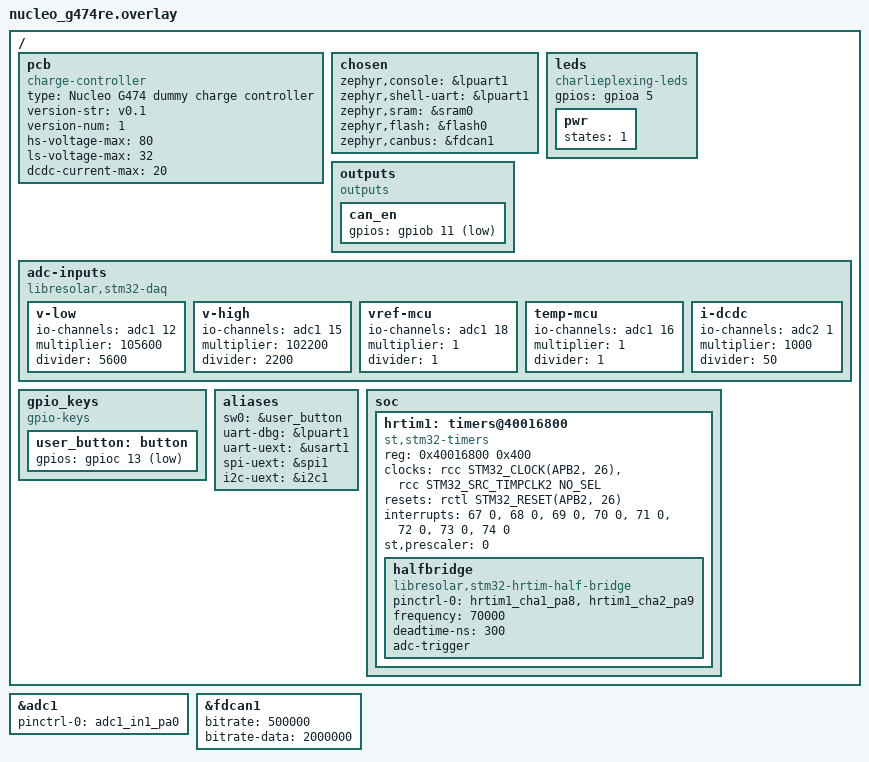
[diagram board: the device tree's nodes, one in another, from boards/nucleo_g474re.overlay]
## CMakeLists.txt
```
# Copyright (c) The Libre Solar Project Contributors
# SPDX-License-Identifier: Apache-2.0

set(BOARD_ROOT ${CMAKE_SOURCE_DIR}/..)
set(DTS_ROOT ${CMAKE_SOURCE_DIR}/..)

cmake_minimum_required(VERSION 3.13.1)
find_package(Zephyr REQUIRED HINTS $ENV{ZEPHYR_BASE})

project(libre_solar_charge_controller)

add_subdirectory(src)

# determine git tag and commit hash for automatic firmware versioning
find_package(Git)
if(GIT_FOUND)
    execute_process(
        COMMAND ${GIT_EXECUTABLE} describe --long --dirty --tags
        OUTPUT_VARIABLE FIRMWARE_VERSION_ID
        OUTPUT_STRIP_TRAILING_WHITESPACE)
else()
    set(FIRMWARE_VERSION_ID "unknown")
endif()
add_definitions(-DFIRMWARE_VERSION_ID="${FIRMWARE_VERSION_ID}")
```

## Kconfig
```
# Copyright (c) The Libre Solar Project Contributors
# SPDX-License-Identifier: Apache-2.0

mainmenu "Libre Solar Charge Controller Firmware"

#
# Invisible (board-specific) Kconfig symbols
#

config CONTROL_FREQUENCY
    int
    default 10
    help
      Main control function frequency (Hz)

      Frequencies higher than 10 Hz caused issues with MPPT control during lab test with
      PV simulator. Might be different with actual solar panel.

config DCDC_DUTY_STEP_SIZE
    int
    default 3 if SOC_SERIES_STM32G4X
    default 1
    help
      Duty cycle change per control step of the DC/DC MPPT algorithm in timer counts of the
      half bridge.

      Larger steps are used for faster microcontrollers, as their half-bridge timers have a
      higher resolution.

config HS_MOSFET_FAIL_SAFE_PROTECTION
    bool
    default y
    depends on $(dt_node_bool_prop,/pcb,ls-fuse)
    help
      If enabled, the DC/DC control function will detect if the high-side MOSFET has failed
      short and trip the fuse by switching the low-side MOSFET continuously on. This will prevent
      accidental overcharging of the battery.

      Only available if the board has a fuse at the low-side terminal (ls-fuse property of the
      pcb devicetree node).

#
# Visible (user-configurable) Kconfig symbols
#

menu "Charge Controller Setup"

choice
    prompt "High-voltage terminal"
    depends on $(dt_nodelabel_enabled,halfbridge)
    help
      Select the device connected to the high-voltage
      side terminal of the DC/DC converter.

    config HV_TERMINAL_SOLAR
        bool "Solar panel"

    config HV_TERMINAL_NANOGRID
        bool "DC nanogrid"

    config HV_TERMINAL_GENERATOR
        bool "DC generator, e.g. wind turbine"

    config HV_TERMINAL_BATTERY
        bool "Battery, e.g. electric bicycle"
endchoice


choice
    prompt "Low-voltage terminal"
    help
      Select the device connected to the low-voltage side
      of the charge controller (usually battery terminal).

    config LV_TERMINAL_BATTERY
        depends on !HV_TERMINAL_BATTERY
        bool "Battery 12V/24V"

    config LV_TERMINAL_SOLAR
        depends on HV_TERMINAL_BATTERY || HV_TERMINAL_NANOGRID
        bool "Solar panel"
endchoice


choice
    prompt "PWM terminal"
    depends on $(dt_nodelabel_enabled,pwm_switch)
    help
      Select the device connected to the PWM switch (currently
      only solar panel possible)

    config PWM_TERMINAL_SOLAR
        depends on LV_TERMINAL_BATTERY && !HV_TERMINAL_SOLAR
        bool "Solar panel"
endchoice


menu "Battery default settings"

config BAT_CAPACITY_AH
    int "Battery nominal capacity in Ah"
    range 10 1000
    default 50
    help
      Nominal battery capacity or sum of parallel cells capacity

choice
    prompt "Battery type"
    default BAT_TYPE_GEL
    help
      Select the type of the single cells inside the battery
      to determine voltage set points. Total voltage set points
      are multiplied with the selected number of cells.

    config BAT_TYPE_CUSTOM
        bool "Custom type"

    config BAT_TYPE_FLOODED
        bool "Flooded (wet) lead-acid"

    config BAT_TYPE_GEL
        bool "VRLA gel, maintainance-free"

    config BAT_TYPE_AGM
        bool "AGM, maintainance-free"

    config BAT_TYPE_LFP
        bool "LiFePO4 Li-ion, 3.3V nominal"

    config BAT_TYPE_NMC
        bool "NMC/Graphite Li-ion, 3.7V nominal, 4.2V max"

    config BAT_TYPE_NMC_HV
        bool "NMC/Graphite High Voltage Li-ion, 3.7V nominal, 4.35 max"
endchoice

# values must match enum BatType in bat_charger.h
config BAT_TYPE
    int
    default 0 if BAT_TYPE_CUSTOM
    default 1 if BAT_TYPE_FLOODED
    default 2 if BAT_TYPE_GEL
    default 3 if BAT_TYPE_AGM
    default 4 if BAT_TYPE_LFP
    default 5 if BAT_TYPE_NMC
    default 6 if BAT_TYPE_NMC_HV

config BAT_NUM_CELLS
    int "Number of cells for single battery"
    default 6 if BAT_TYPE_FLOODED || BAT_TYPE_GEL || BAT_TYPE_AGM
    default 4 if BAT_TYPE_LFP
    default 3 if BAT_TYPE_NMC || BAT_TYPE_NMC_HV
    range 3 16
    help
      Typical choices:
      - 6 for 12V lead-acid battery
      - 4 for 12V LiFePO4 battery
      - 3 for 12V NMC Li-ion battery

      Remarks:
      - If you choose settings for 12V system, 24V systems
        (2 batteries in series) are recognized automatically
      - Make sure the voltage of the used charge controller
        is not exceeded.

menu "Custom cell-level settings"
    depends on BAT_TYPE_CUSTOM

config CELL_ABS_MAX_VOLTAGE_MV
    int "Absolute maximum voltage (mV)"
    default 2450
    help
      Above this voltage the battery or loads might get damaged.

config CELL_TOPPING_VOLTAGE_MV
    int "Topping voltage (mV)"
    default 2400
    help
      Charger target voltage, switching from CC to CV at this voltage threshold.

config CELL_RECHARGE_VOLTAGE_MV
    int "Recharge voltage (mV)"
    default 2300
    help
      Start charging again if voltage of fully charged battery drops below this threshold.

config CELL_RECONNECT_VOLTAGE_MV
    int "Load reconnect cell voltage (mV)"
    default 2100
    help
      Re-enable the load only after charged beyond this value.

config CELL_DISCONNECT_VOLTAGE_MV
    int "Load disconnect cell voltage (mV)"
    default 1950
    help
      Load output is disabled if battery voltage is below this threshold.

config CELL_ABS_MIN_VOLTAGE_MV
    int "Topping voltage (mV)"
    default 1600
    help
      Below this voltage the battery is considered damaged.

config CELL_OCV_FULL_MV
    int "OCV full cell (mV)"
    default 2150
    help
      Voltages during idle (no charging/discharging current)

config CELL_OCV_EMPTY_MV
    int "OCV empty cell (mV)"
    default 1900
    help
      Voltages during idle (no charging/discharging current)

config CELL_FLOAT
    bool "Enable float charging phase"
    default y

config CELL_FLOAT_VOLTAGE_MV
    int "Float charging cell voltage (mV)" if CELL_FLOAT
    default 2300
    help
      Charger target voltage for float charging of lead-acid batteries

config CELL_FLOAT_RECHARGE_TIME
    int "Float recharge time (s)" if CELL_FLOAT
    default 1800
    help
      If the float voltage is not reached anymore (e.g. because of lack of solar
      input power) for this period of time, the charger state machine goes back
      into CC/bulk charging mode.

config CELL_EQUALIZATION
    bool "Enable equalization phase"
    default n
    help
      Enable for flooded batteries only.

config CELL_EQUALIZATION_VOLTAGE_MV
    int "Equalization phase cell voltage (mV)" if CELL_EQUALIZATION
    default 2450
    help
      Charger target voltage for equalization charging of lead-acid batteries

config CELL_EQUALIZATION_DURATION
    int "Equalization duration (seconds)" if CELL_EQUALIZATION
    default 3600
    help
      After this time, equalization charging is stopped.

config CELL_EQUALIZATION_TRIGGER_DAYS
    int "Equalization time trigger (days)" if CELL_EQUALIZATION
    default 60
    help
      After passing specified amount of days, an equalization charge is triggered.

config CELL_EQUALIZATION_TRIGGER_DEEP_CYCLES
    int "Equalization deep cycle count trigger" if CELL_EQUALIZATION
    default 10
    help
      After specified number of deep discharges, an equalization charge is triggered.

config CELL_TEMP_COMPENSATION_MV_K
    int "Cell voltage temperature compenstaion (mV/K)"
    range -5 0
    default -3
    help
      Suggested value: -3 mV/K/cell for lead-acid batteries, 0 for Li-ion batteries

config CELL_INTERNAL_RESISTANCE_MOHM
    int "Cell internal resistance (mOhm)"
    range 1 30
    default 5

endmenu # Custom cell-level settings

menu "Custom temperature settings"
    depends on BAT_TYPE_CUSTOM

config BAT_CHARGE_TEMP_MAX
    int "Maximum charge temperature (°C)"
    range 0 60
    default 50

config BAT_CHARGE_TEMP_MIN
    int "Minimum charge temperature (°C)"
    range -10 20
    default 0

config BAT_DISCHARGE_TEMP_MAX
    int "Maximum discharge temperature (°C)"
    range 0 60
    default 50

config BAT_DISCHARGE_TEMP_MIN
    int "Minimum discharge temperature (°C)"
    range -20 20
    default -10

endmenu # Custom temperature settings

endmenu # Battery default settings


menu "Load output settings"
    depends on $(dt_nodelabel_enabled,load_switch)

config LOAD_OC_RECOVERY_DELAY
    int "Overcurrent recovery delay (s)"
    default 300

config LOAD_LVD_RECOVERY_DELAY
    int "Low-voltage disconnect recovery delay (s)"
    default 300
    help
      Prevents toggling load output in case of heavy load and low state of charge.

endmenu # Load output settings


endmenu # Charge controller setup


menu "UEXT port"

DT_CHOSEN_Z_DISPLAY := zephyr,display

config UEXT_OLED_DISPLAY
    bool "OLED display"
    depends on $(dt_chosen_enabled,$(DT_CHOSEN_Z_DISPLAY))
    default y if SHIELD_UEXT_OLED
    select DISPLAY
    select CHARACTER_FRAMEBUFFER
    help
      Show live data on a SSD1306 128x64 OLED display connected to the UEXT
      port. The display is configured via the uext_oled shield:

        west build -b <board> app -- -DSHIELD=uext_oled

      The brightness can be changed via CONFIG_SSD1306_DEFAULT_CONTRAST.

config HEAP_MEM_POOL_ADD_SIZE_UEXT_OLED
    int
    default 1280 if UEXT_OLED_DISPLAY
    default 0
    help
      Frame buffer allocated by the character framebuffer subsystem (1024 bytes) plus some
      margin for the heap management overhead.

config CHARACTER_FRAMEBUFFER_USE_DEFAULT_FONTS
    default n if UEXT_OLED_DISPLAY

endmenu # UEXT port

menu "Logging setup"

config CAN_LOG_LEVEL
    int "Log level for the CAN module (if included)"
    default 2
    depends on LOG
    help
      Log level for the CAN module (if included). 0=off, 1=ERR, 2=WRN, 3=INF, 4=DBG

config DATA_OBJECTS_LOG_LEVEL
    int "Log level for the data objects module"
    default 2
    depends on LOG
    help
      Log level for the data nodes module. 0=off, 1=ERR, 2=WRN, 3=INF, 4=DBG

config DATA_STORAGE_LOG_LEVEL
    int "Log level for the data storage module"
    default 2
    depends on LOG
    help
      Log level for the data storage module. 0=off, 1=ERR, 2=WRN, 3=INF, 4=DBG

config DCDC_LOG_LEVEL
    int "Log level for the DCDC module (if included)"
    default 2
    depends on LOG
    help
      Log level for the DCDC module (if included). 0=off, 1=ERR, 2=WRN, 3=INF, 4=DBG

config BAT_LOG_LEVEL
    int "Log level for the battery module"
    default 2
    depends on LOG
    help
      Log level for the battery module. 0=off, 1=ERR, 2=WRN, 3=INF, 4=DBG

config LOAD_LOG_LEVEL
    int "Log level for the load output module (if included)"
    default 2
    depends on LOG
    help
      Log level for the load output module (if included). 0=off, 1=ERR, 2=WRN, 3=INF, 4=DBG

config PWM_LOG_LEVEL
    int "Log level for the PWM module (if included)"
    default 2
    depends on LOG
    help
      Log level for the PWM module (if included). 0=off, 1=ERR, 2=WRN, 3=INF, 4=DBG

endmenu # Logging setup

menuconfig CUSTOMIZATION
    bool "Firmware customization"
    help
      Activating this option allows to overwrite existing firmware functions
      or add customizations independent of the main branch.
      Custom implementations should be stored in the
      src/custom subdirectory.

if CUSTOMIZATION

config CUSTOM_DATA_OBJECTS_FILE
    bool "Use custom data nodes file"
    default n
    help
      Use the file data_objects_custom.cpp instead of the default data_objects.cpp
      for ThingSet configuration.

config CUSTOM_DCDC_CONTROLLER
    bool "Custom implementation of DC/DC controller"
    depends on $(dt_nodelabel_enabled,halfbridge)
    default n
    help
      Use a custom implementation instead of the default perturb & observe
      MPPT control.

endif

# include custom Kconfig if existing
orsource "../src/custom/Kconfig"

# include main Zephyr menu entries from Zephyr root directory
source "Kconfig.zephyr"
```

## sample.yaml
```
sample:
  name: Libre Solar charge controller firmware
common:
  build_only: true
  tags:
    - charge_controller
tests:
  charge_controller.firmware:
    platform_allow: &boards
      - mppt_1210_hus@0.4.0
      - mppt_1210_hus@0.7.0
      - mppt_2420_hc@0.1.0
      - mppt_2420_hc@0.2.0
      - mppt_2420_hpx
      - mppt_2420_lc
      - mppt_2420_rc
      - nucleo_g474re
      - pwm_2420_lus@0.2.0
      - pwm_2420_lus@0.3.0
    integration_platforms: *boards
  charge_controller.firmware.uext_oled:
    extra_args: SHIELD=uext_oled
    # mppt_2420_lc and nucleo_g474re excluded: not enough RAM / no UEXT port
    platform_allow: &uext_oled_boards
      - mppt_1210_hus@0.7.0
      - mppt_2420_hc@0.2.0
      - mppt_2420_hpx
      - mppt_2420_rc
      - pwm_2420_lus@0.3.0
    integration_platforms: *uext_oled_boards
```

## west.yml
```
manifest:
  remotes:
    - name: zephyrproject
      url-base: https://github.com/zephyrproject-rtos
    - name: libresolar
      url-base: https://github.com/LibreSolar
    - name: thingset
      url-base: https://github.com/ThingSet
    - name: throwtheswitch
      url-base: https://github.com/ThrowTheSwitch
  projects:
    - name: zephyr
      remote: zephyrproject
      revision: v2.7-branch
      import:
        name-allowlist:
          - cmsis
          - edtt
          - hal_stm32
    - name: oled-display-library
      remote: libresolar
      revision: cc3033c0daace8cb50ab0e6406a9498cc81cdb39
      path: modules/oled-display
    - name: thingset-device-library
      remote: thingset
      revision: 1eaa305a9f1873f676b77b8dd0f9d34f1944ecd1
      path: modules/thingset
    - name: unity
      remote: throwtheswitch
      revision: 74cde089e65c3435ce9aa87d5c69f4f16b7f6ade
      path: modules/unity
```

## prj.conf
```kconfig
# Main application configuration (overrides board-specific settings)

# only very small heap necessary for malloc in printf statements with %f
CONFIG_HEAP_MEM_POOL_SIZE=256

CONFIG_CPP=y
CONFIG_REQUIRES_FULL_LIBCPP=y

CONFIG_PICOLIBC_IO_FLOAT=y

CONFIG_WATCHDOG=y
CONFIG_TASK_WDT=y
CONFIG_THREAD_NAME=y

CONFIG_REBOOT=y

CONFIG_HWINFO=y

CONFIG_CRC=y

# NTC temperature sensors
CONFIG_SENSOR=y

CONFIG_CONSOLE_SUBSYS=y
CONFIG_CONSOLE_GETCHAR=y

# Use minimal logging by default to save memory for STM32F0 with little RAM
CONFIG_LOG=y
CONFIG_LOG_MODE_MINIMAL=y

CONFIG_THINGSET=y
CONFIG_THINGSET_SDK=y
CONFIG_THINGSET_STORAGE=y
CONFIG_THINGSET_SERIAL=y
CONFIG_THINGSET_STORAGE_DATA_VERSION=6
CONFIG_THINGSET_NODE_NAME="Libre Solar MPPT"

# Must be lower than LED thread to avoid flickering in boards with charlieplexing
CONFIG_THINGSET_SDK_THREAD_PRIORITY=6

# Uncomment to disable regular data publication on ThingSet serial at startup
#CONFIG_THINGSET_REPORTING_LIVE_ENABLE_PRESET=n

# I2C OLED display in UEXT connector is enabled by building with -DSHIELD=uext_oled

# Select initial battery configuration: GEL (default), FLOODED, AGM, LFP, NMC or NMC_HV
#CONFIG_BAT_TYPE_???=y

# Change number of cells considering selected type (12V/24V battery by default if not set)
#CONFIG_BAT_NUM_CELLS=?
```

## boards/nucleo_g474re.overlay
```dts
/*
 * Copyright (c) The Libre Solar Project Contributors
 *
 * SPDX-License-Identifier: Apache-2.0
 *
 * This is a dummy charge controller board for testing new features using the STM32G474 MCU
 *
 * IMPORTANT: You have to remove the VREF jumper on the Nucleo board to make it work. Otherwise
 *            the MCU will get stuck while trying to generate a reference voltage at VREF+ pin.
 */

/ {
	/* delete conflicting nodes from Zephyr board */
	/delete-node/ leds;
	/delete-node/ aliases;

	pcb {
		compatible = "charge-controller";

		type = "Nucleo G474 dummy charge controller";
		version-str = "v0.1";
		version-num = <1>;

		hs-voltage-max = <80>;
		ls-voltage-max = <32>;
		dcdc-current-max = <20>;
	};

	chosen {
		zephyr,console = &lpuart1;
		zephyr,shell-uart = &lpuart1;
		zephyr,sram = &sram0;
		zephyr,flash = &flash0;
		zephyr,canbus = &fdcan1;
	};

	leds {
		compatible = "charlieplexing-leds";
		gpios = <&gpioa 5 GPIO_ACTIVE_HIGH>;

		pwr {
			states = <1>;
		};
	};

	outputs {
		compatible = "outputs";

		can_en {
			gpios = <&gpiob 11 GPIO_ACTIVE_LOW>;
		};
	};

	adc-inputs {
		compatible = "libresolar,stm32-daq";

		v-low {
			io-channels = <&adc1 12>;
			multiplier = <105600>;
			divider = <5600>;
		};

		v-high {
			io-channels = <&adc1 15>;
			multiplier = <102200>;
			divider = <2200>;
		};

		vref-mcu {
			io-channels = <&adc1 18>;
			multiplier = <1>;
			divider = <1>;
		};

		temp-mcu {
			io-channels = <&adc1 16>;
			multiplier = <1>;
			divider = <1>;
		};

		i-dcdc {
			io-channels = <&adc2 1>;
			// amp gain: 25, resistor: 2 mOhm
			multiplier = <1000>;	// 1000
			divider = <50>;	// 2*25
		};
	};

	gpio_keys {
		compatible = "gpio-keys";
		user_button: button {
			gpios = <&gpioc 13 GPIO_ACTIVE_LOW>;
		};
	};

	aliases {
		sw0 = &user_button;
		uart-dbg = &lpuart1;
		uart-uext = &usart1;
		spi-uext = &spi1;
		i2c-uext = &i2c1;
	};

	soc {
		hrtim1: timers@40016800 {
			compatible = "st,stm32-timers";
			reg = <0x40016800 0x400>;
			clocks = <&rcc STM32_CLOCK(APB2, 26)>,
				 <&rcc STM32_SRC_TIMPCLK2 NO_SEL>;
			resets = <&rctl STM32_RESET(APB2, 26)>;
			interrupts = <67 0>, <68 0>, <69 0>, <70 0>,
				     <71 0>, <72 0>, <73 0>, <74 0>;
			interrupt-names = "master", "tima", "timb", "timc",
					  "timd", "time", "flt", "timf";
			st,prescaler = <0>;
			status = "disabled";
		};
	};
};

&hrtim1 {
	status = "okay";

	halfbridge: halfbridge {
		compatible = "libresolar,stm32-hrtim-half-bridge";
		pinctrl-0 = <&hrtim1_cha1_pa8 &hrtim1_cha2_pa9>;
		pinctrl-names = "default";
		frequency = <70000>;
		deadtime-ns = <300>;
		adc-trigger;
	};
};

/*
// alternative to HRTIM
&timers1 {
	status = "okay";

	halfbridge: halfbridge {
		compatible = "libresolar,stm32-advtim-half-bridge";
		pinctrl-0 = <&tim1_ch1_pa8 &tim1_ch1n_pb13>;
		pinctrl-names = "default";
		channel = <1>;
		frequency = <70000>;
		deadtime-ns = <300>;
		adc-trigger;
	};
};
*/

&adc1 {
	pinctrl-0 = <&adc1_in1_pa0>;
	pinctrl-names = "default";
	status = "okay";
};

&fdcan1 {
	bitrate = <500000>;
	bitrate-data = <2000000>;
	status = "okay";
};
```

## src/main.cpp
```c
/*
 * Copyright (c) The Libre Solar Project Contributors
 *
 * SPDX-License-Identifier: Apache-2.0
 */

#ifndef UNIT_TEST

#include <stdio.h>
#include <zephyr/device.h>
#include <zephyr/drivers/gpio.h>
#include <zephyr/kernel.h>
#include <zephyr/task_wdt/task_wdt.h>

#include "helper.h"
#include "setup.h"

#include <libresolar/drivers/half_bridge.h>

#include "bat_charger.h"   // battery settings and charger state machine
#include "daq.h"           // ADC using DMA and conversion to measurement values
#include "data_objects.h"  // for access to internal data via ThingSet
#include "dcdc.h"          // DC/DC converter control (hardware independent)
#include "device_status.h" // log data (error memory, min/max measurements, etc.)
#include "hardware.h" // hardware-related functions like load switch, LED control, watchdog, etc.
#include "leds.h"     // LED switching using charlieplexing
#include "load.h"     // load and USB output management
#if BOARD_HAS_PWM_PORT
#include "pwm_switch.h" // PWM charge controller
#endif

int main(void)
{
    printf("Hardware: Libre Solar %s (%s)\n", DT_PROP(DT_PATH(pcb), type),
           DT_PROP(DT_PATH(pcb), version_str));
    printf("Firmware: %s\n", FIRMWARE_VERSION_ID);

    task_wdt_init(DEVICE_DT_GET_OR_NULL(DT_NODELABEL(iwdg)));

    setup();

    battery_conf_init(&bat_conf, CONFIG_BAT_TYPE, CONFIG_BAT_NUM_CELLS, CONFIG_BAT_CAPACITY_AH);
    battery_conf_overwrite(&bat_conf, &bat_conf_user); // initialize conf_user with same values

#if CONFIG_HV_TERMINAL_SOLAR || CONFIG_LV_TERMINAL_SOLAR || CONFIG_PWM_TERMINAL_SOLAR
    power_port_init_solar(&solar_terminal);
#endif

#if CONFIG_HV_TERMINAL_NANOGRID
    power_port_init_nanogrid(&grid_terminal);
#endif

    // make sure loaded configuration is valid
    data_objects_init();

    // Data Acquisition (DAQ) setup
    daq_setup();

#if BOARD_HAS_DCDC
    // requires the reference voltage, which may be calculated from initial measurements
    daq_set_hv_limit(DT_PROP(DT_PATH(pcb), hs_voltage_max));
#endif

    charger.detect_num_batteries(&bat_conf); // check if we have 24V instead of 12V system
    charger.init_terminal(&bat_conf);

#if BOARD_HAS_LOAD_OUTPUT
    load.set_voltage_limits(bat_conf.load_disconnect_voltage, bat_conf.load_reconnect_voltage,
                            bat_conf.absolute_max_voltage);
#endif

#if BOARD_HAS_USB_OUTPUT
    usb_pwr.set_voltage_limits(bat_conf.load_disconnect_voltage - 0.1f, // keep on longer than load
                               bat_conf.load_reconnect_voltage, bat_conf.absolute_max_voltage);
#endif

    // wait until all threads are spawned before activating the watchdog
    k_sleep(K_MSEC(2500));

    int64_t t_start = k_uptime_get();

    while (true) {
        // loop runs exactly once per second and includes slow control tasks and energy calculation

        charger.discharge_control(&bat_conf);
        charger.charge_control(&bat_conf);

// energy + soc calculation must be called exactly once per second
#if BOARD_HAS_DCDC
        if (dcdc.state != DCDC_CONTROL_OFF) {
            power_port_energy_balance(&hv_terminal);
        }
#endif

#if BOARD_HAS_PWM_PORT
        if (pwm_switch.active() == 1) {
            power_port_energy_balance(&pwm_switch);
        }
#endif

        power_port_energy_balance(&lv_terminal);

#if BOARD_HAS_LOAD_OUTPUT
        if (load.state == 1) {
            power_port_energy_balance(&load);
        }
#endif

        device_status_update_energy(&dev_stat);
        device_status_update_min_max_values(&dev_stat);
        charger.update_soc(&bat_conf);

#if CONFIG_HS_MOSFET_FAIL_SAFE_PROTECTION && BOARD_HAS_DCDC
        if (device_status_has_error(&dev_stat, ERR_DCDC_HS_MOSFET_SHORT)) {
            dcdc_fuse_destruction(&dcdc);
        }
#endif

        leds_update_1s();

#if BOARD_HAS_LOAD_OUTPUT
        leds_update_soc(charger.soc, flags_check(&load.error_flags, ERR_LOAD_SHEDDING));
#else
        leds_update_soc(charger.soc, false);
#endif

        t_start += 1000;
        k_sleep(K_TIMEOUT_ABS_MS(t_start));
    }
}

void control_thread()
{
    int wdt_channel = task_wdt_add(200, task_wdt_callback, (void *)k_current_get());

    while (true) {
        // control loop runs at approx. 10 Hz

        bool charging = false;

        task_wdt_feed(wdt_channel);

        // convert ADC readings to meaningful measurement values
        daq_update();

        // alerts should trigger only for transients, so update based on actual voltage
        daq_set_lv_limits(lv_terminal.bus->voltage * 1.2F, lv_terminal.bus->voltage * 0.8F);

        power_port_update_bus_current_margins(&lv_terminal);

#if BOARD_HAS_PWM_PORT
        pwm_switch.control();
        charging |= pwm_switch.active();
#endif

#if BOARD_HAS_DCDC
        power_port_update_bus_current_margins(&hv_terminal);
        dcdc_control(&dcdc); // control of DC/DC including MPPT algorithm
        charging |= half_bridge_is_enabled(dcdc.half_bridge);
#endif

        leds_set_charging(charging);

#if BOARD_HAS_LOAD_OUTPUT
        load.control();
#endif

#if BOARD_HAS_USB_OUTPUT
        usb_pwr.control();
#endif

        k_sleep(K_MSEC(100));
    }
}

// 2s delay for control thread as a safety feature: be able to re-flash before starting
// priority is set to -1 (=cooperative) to have higher priority than other threads incl. main
K_THREAD_DEFINE(control_thread_id, 1024, control_thread, NULL, NULL, NULL, -1, 0, 2000);

#endif // UNIT_TEST
```

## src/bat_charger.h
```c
/*
 * Copyright (c) The Libre Solar Project Contributors
 *
 * SPDX-License-Identifier: Apache-2.0
 */

#ifndef BAT_CHARGER_H
#define BAT_CHARGER_H

/** @file
 *
 * @brief Battery and charger configuration and functions
 */

#include <stdbool.h>
#include <stddef.h>
#include <stdint.h>
#include <time.h>

#include "power_port.h"

#define CHARGER_TIME_NEVER INT32_MIN

/**
 * Battery cell types
 */
enum BatType
{
    /*
     * IMPORTANT: make sure to adjust also boards/Kconfig if enum is changed here!
     */
    BAT_TYPE_CUSTOM = 0, ///< Custom battery type
    BAT_TYPE_FLOODED,    ///< Old flooded (wet) lead-acid batteries
    BAT_TYPE_GEL,        ///< VRLA gel batteries (maintainance-free)
    BAT_TYPE_AGM,        ///< AGM batteries (maintainance-free)
    BAT_TYPE_LFP,        ///< LiFePO4 Li-ion batteries (3.3V nominal)
    BAT_TYPE_NMC,        ///< NMC/Graphite Li-ion batteries (3.7V nominal)
    BAT_TYPE_NMC_HV,     ///< NMC/Graphite High Voltage Li-ion batteries (3.7V nominal, 4.35 max)
};

/**
 * Battery configuration data
 *
 * Data will be initialized in battery_init depending on configured cell type in config.h.
 */
typedef struct
{
    /**
     * Nominal battery capacity or sum of parallel cells capacity (Ah)
     *
     * The nominal capacity is used for SOC calculation and definition of current limits.
     */
    float nominal_capacity;

    /**
     * Recharge voltage (V)
     *
     * Start charging again if voltage of fully charged battery drops below this threshold.
     *
     * Remark: Setting the value too close to the max voltage will cause more charging stress on
     * lithium based batteries.
     */
    float recharge_voltage;

    /**
     * Recharge time limit (sec)
     *
     * Start charging of previously fully charged battery earliest after this period of time.
     */
    uint32_t time_limit_recharge;

    /**
     * Absolute maximum voltage (V)
     *
     * Above this voltage the battery or loads might get damaged.
     */
    float absolute_max_voltage;

    /**
     * Absolute minimum voltage (V)
     *
     * Below this voltage the battery is considered damaged.
     */
    float absolute_min_voltage;

    /**
     * Maximum charge current in *CC/bulk* phase (A)
     *
     * Limits the current if the PCB allows more than the battery. (positive value)
     */
    float charge_current_max;

    /**
     * Maximum discharge current via load port (A)
     *
     * Limits the current if the PCB allows more than the battery. (positive value)
     */
    float discharge_current_max;

    /**
     * Maximum voltage in CV/absorption phase (V)
     *
     * Charger target voltage, switching from CC to CV at this voltage threshold.
     */
    float topping_voltage;

    /**
     * CV phase cut-off current limit (A)
     *
     * Constant voltage charging phase stopped if current is below this value.
     */
    float topping_cutoff_current;

    /**
     * CV phase cut-off time limit (s)
     *
     * After this time, CV charging is stopped independent of current.
     */
    uint32_t topping_duration;

    /**
     * Enable float/trickle charging
     *
     * Caution: Do not enable float charging for lithium-ion batteries
     */
    bool float_enabled;

    /**
     * Float voltage (V)
     *
     * Charger target voltage for float charging of lead-acid batteries
     */
    float float_voltage;

    /**
     * Float recharge time (s)
     *
     * If the float voltage is not reached anymore (e.g. because of lack of solar
     * input power) for this period of time, the charger state machine goes back
     * into CC/bulk charging mode.
     */
    uint32_t float_recharge_time;

    /**
     * Enable equalization charging
     *
     * Caution: Do not enable float charging for lithium-ion batteries
     */
    bool equalization_enabled;

    /**
     * Equalization voltage (V)
     *
     * Charger target voltage for equalization charging of lead-acid batteries
     */
    float equalization_voltage;

    /**
     * Equalization cut-off time limit (s)
     *
     * After this time, equalization charging is stopped.
     */
    uint32_t equalization_duration;

    /**
     * Equalization phase maximum current (A)
     *
     * The current of the charger is controlled to stay below this limit during equalization.
     */
    float equalization_current_limit;

    /**
     * Equalization trigger time interval (days)
     *
     * After passing specified amount of days, an equalization charge is triggered.
     */
    uint32_t equalization_trigger_days;

    /**
     * Equalization trigger deep-discharge cycles
     *
     * After specified number of deep discharges, an equalization charge is triggered.
     */
    uint32_t equalization_trigger_deep_cycles;

    /**
     * Load disconnect open circuit voltage (V)
     *
     * Load output is disabled if battery voltage is below this threshold.
     *
     * The voltage is current-compensated using the battery internal resistance:
     * threshold = load_disconnect_voltage + battery_current * internal_resistance
     *
     * (Remark: battery_current negative during discharge, internal_resistance positive)
     */
    float load_disconnect_voltage;

    /**
     * Load reconnect open circuit voltage (V)
     *
     * Re-enable the load only after charged beyond this value.
     *
     * The voltage is current-compensated using the battery internal resistance:
     * threshold = load_reconnect_voltage + battery_current * internal_resistance
     *
     * (Remark: battery_current positive during charge, internal_resistance positive)
     */
    float load_reconnect_voltage;

    /**
     * Battery internal resistance (Ohm)
     *
     * Resistance value for current-compensation of load switch voltage thresholds.
     *
     * The value must have a positive sign. Only resistance values leading to less than 10% voltage
     * drop at max. current are allowed.
     */
    float internal_resistance;

    /**
     * Resistance of wire between charge controller and battery (Ohm)
     *
     * Resistance value for current-compensation of charging voltages.
     *
     * The value must have a positive sign. Only resistance values leading to less than 3% voltage
     * loss at max. current are allowed.
     */
    float wire_resistance;

    /**
     * Open circuit voltage of full battery (V)
     *
     * Used for simple state of charge (SOC) algorithm.
     */
    float ocv_full;

    /**
     * Open circuit voltage of empty battery (V)
     *
     * Used for simple state of charge (SOC) algorithm.
     */
    float ocv_empty;

    /**
     * Maximum allowed charging temperature of the battery (°C)
     */
    float charge_temp_max;

    /**
     * Minimum allowed charging temperature of the battery (°C)
     */
    float charge_temp_min;

    /**
     * Maximum allowed discharging temperature of the battery (°C)
     */
    float discharge_temp_max;

    /**
     * Minimum allowed discharging temperature of the battery (°C)
     */
    float discharge_temp_min;

    /**
     * Voltage compensation based on battery temperature (mV/K/cell)
     *
     * Suggested value: -3 mV/K/cell
     */
    float temperature_compensation;

} BatConf;

/**
 * Possible charger states
 *
 * Further information:
 * - https://en.wikipedia.org/wiki/IUoU_battery_charging
 * - https://batteryuniversity.com/learn/article/charging_the_lead_acid_battery
 */
enum ChargerState
{
    /**
     * Idle
     *
     * Initial state of the charge controller. If the solar voltage is high enough
     * and the battery is not full, bulk charging mode is started.
     */
    CHG_STATE_IDLE,

    /**
     * Bulk / CC / MPPT charging
     *
     * The battery is charged with maximum possible current (MPPT algorithm is
     * active) until the CV voltage limit is reached.
     */
    CHG_STATE_BULK,

    /**
     * Topping / CV / absorption charging
     *
     * Lead-acid batteries are charged for some time using a slightly higher charge
     * voltage. After a current cutoff limit or a time limit is reached, the charger
     * goes into float or equalization mode for lead-acid batteries or back into
     * Standby for Li-ion batteries.
     */
    CHG_STATE_TOPPING,

    /**
     * Float / trickle charging
     *
     * This mode is kept forever for a lead-acid battery and keeps the battery at
     * full state of charge. If too much power is drawn from the battery, the
     * charger switches back into CC / bulk charging mode.
     */
    CHG_STATE_FLOAT,

    /**
     * Equalization charging
     *
     * This mode is only used for lead-acid batteries after several deep-discharge
     * cycles or a very long period of time with no equalization. Voltage is
     * increased to 15V or above, so care must be taken for the other system
     * components attached to the battery. (currently, no equalization charging is
     * enabled in the software)
     */
    CHG_STATE_EQUALIZATION,

    /**
     * Parallel operation of multiple converters
     *
     * This mode is enabled if the device receives commands from an external controller with
     * higher priority on the CAN bus. The device goes in current control modes and tries to
     * match the current of the other controller.
     */
    CHG_STATE_FOLLOWER,
};

/**
 * Charger configuration and battery state
 */
class Charger
{
public:
    Charger(struct power_port *pwr_port) : port(pwr_port) {};

    struct power_port *port;

    /**
     * Current charger state (see enum ChargerState)
     */
    uint32_t state = CHG_STATE_IDLE;

    /**
     * Battery temperature (°C) from ext. temperature sensor (if existing)
     */
    float bat_temperature = 25;

    /**
     * Flag to indicate if external temperature sensor was detected
     */
    bool ext_temp_sensor;

    /**
     * Estimated usable capacity (Ah) based on coulomb counting
     */
    float usable_capacity;

    /**
     * Coulomb counter for SOH calculation
     */
    float discharged_Ah;

    /**
     * Number of full charge cycles
     */
    uint16_t num_full_charges;

    /**
     * Number of deep-discharge cycles
     */
    uint16_t num_deep_discharges;

    /**
     * State of Charge (%)
     */
    uint16_t soc = 100;

    /**
     * State of Health (%)
     */
    uint16_t soh = 100;

    /**
     * Timestamp of last state change
     */
    time_t time_state_changed = CHARGER_TIME_NEVER;

    /**
     * Last time the CV limit was reached
     */
    time_t time_target_voltage_reached = CHARGER_TIME_NEVER;

    /**
     * Counts the number of seconds during which the target voltage of current charging phase was
     * reached.
     */
    uint32_t target_voltage_timer;

    /**
     * Timestamp after finish of last equalization charge
     */
    time_t time_last_equalization = CHARGER_TIME_NEVER;

    /**
     * Deep discharge counter value after last equalization
     */
    uint32_t deep_dis_last_equalization;

    /**
     * Flag to indicate if battery was fully charged
     */
    bool full;

    /**
     * Flag to indicate if battery was completely discharged
     */
    bool empty;

    /**
     * Last time a control message from external device was received
     */
    time_t time_last_ctrl_msg = CHARGER_TIME_NEVER;

    /**
     * Target current of the converter if operating in follower mode (received from external
     * converter with higher priority via CAN)
     */
    float target_current_control;

    /**
     * Detect if two batteries are connected in series (12V/24V auto-detection)
     */
    void detect_num_batteries(BatConf *bat) const;

    /**
     * Discharging control update (for load output), should be called once per second
     */
    void discharge_control(BatConf *bat_conf);

    /**
     * Charger state machine update, should be called once per second
     */
    void charge_control(BatConf *bat_conf);

    /**
     * SOC estimation
     *
     * Must be called exactly once per second, otherwise SOC calculation gets wrong.
     */
    void update_soc(BatConf *bat_conf);

    /**
     * Initialize terminal and dc bus for battery connection
     *
     * @param bat Configuration to be used for terminal setpoints
     */
    void init_terminal(BatConf *bat) const;

private:
    void enter_state(int next_state);
};

/**
 * Basic initialization of battery configuration
 *
 * Configures battery based on settings defined in config.h and initializes
 * bat_user with same values
 *
 * @param bat Battery configuration that should be initialized
 * @param type Battery type, one of enum BatType (declared as int instead of enum BatType because
 *             configuration via Kconfig symbol cannot handle enums)
 * @param num_cells Number of cells (e.g. 6 for 12V lead-acid battery)
 * @param nominal_capacity Nominal capacity (Ah)
 */
void battery_conf_init(BatConf *bat, int type, int num_cells, float nominal_capacity);

/**
 * Checks battery user settings for plausibility
 */
bool battery_conf_check(BatConf *bat);

/**
 * Overwrites battery settings (config should be checked first)
 *
 * Settings specified in bat_user will be copied to actual battery_t,
 * if suggested updates are valid (includes plausibility check!)
 */
void battery_conf_overwrite(BatConf *source, BatConf *destination, Charger *charger = NULL);

/**
 * Checks if incoming configuration is different to current configuration
 *
 * Returns true if changed
 */
bool battery_conf_changed(BatConf *a, BatConf *b);

#endif /* BAT_CHARGER_H */
```

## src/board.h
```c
/*
 * Copyright (c) The Libre Solar Project Contributors
 *
 * SPDX-License-Identifier: Apache-2.0
 */

#ifndef BOARD_H_
#define BOARD_H_

/**
 * @file
 *
 * @brief Defines for conditional compiling based on existing board features
 */

#include <zephyr/kernel.h>

#define HALF_BRIDGE_NODE      DT_NODELABEL(halfbridge)
#define LOAD_SWITCH_NODE      DT_NODELABEL(load_switch)
#define USB_SWITCH_NODE       DT_NODELABEL(usb_switch)
#define PWM_SWITCH_NODE       DT_NODELABEL(pwm_switch)
#define NTC_FETS_NODE         DT_NODELABEL(ntc_fets)
#define NTC_BAT_NODE          DT_NODELABEL(ntc_bat)
#define BOARD_HAS_DCDC        DT_NODE_HAS_STATUS_OKAY(HALF_BRIDGE_NODE)
#define BOARD_HAS_PWM_PORT    DT_NODE_HAS_STATUS_OKAY(PWM_SWITCH_NODE)
#define BOARD_HAS_LOAD_OUTPUT DT_NODE_HAS_STATUS_OKAY(LOAD_SWITCH_NODE)
#define BOARD_HAS_USB_OUTPUT  DT_NODE_HAS_STATUS_OKAY(USB_SWITCH_NODE)
#define BOARD_HAS_TEMP_FETS   DT_NODE_HAS_STATUS_OKAY(NTC_FETS_NODE)
#define BOARD_HAS_TEMP_BAT    DT_NODE_HAS_STATUS_OKAY(NTC_BAT_NODE)

#endif /* BOARD_H_ */
```

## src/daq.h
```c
/*
 * Copyright (c) The Libre Solar Project Contributors
 *
 * SPDX-License-Identifier: Apache-2.0
 */

/**
 * @file
 * @brief Data Acquisition (DAQ)
 *
 * Measurements are taken by the DAQ driver. This module converts them to the measurement values
 * stored in the structs of the power ports and DC buses, which are afterwards used by the control
 * algorithms.
 */

#ifndef DAQ_H_
#define DAQ_H_

#include <libresolar/drivers/daq.h>

#include <zephyr/device.h>
#include <zephyr/devicetree.h>

#ifdef __cplusplus
extern "C" {
#endif

/** DAQ devicetree node */
#define DAQ_NODE DT_PATH(adc_inputs)

/** DAQ device */
#define DAQ_DEV DEVICE_DT_GET(DAQ_NODE)

/**
 * Get the channel index of a DAQ input
 *
 * @param name Lower-case-and-underscores name of the child node of the DAQ node, e.g. v_low
 */
#define DAQ_CH(name) DAQ_CHANNEL(DAQ_NODE, name)

/**
 * Set offset vs. actual measured value, i.e. sets zero current point.
 *
 * All input/output switches and consumers should be switched off before calling this function
 */
void calibrate_current_sensors(void);

/**
 * Updates structures with data read from ADC
 */
void daq_update(void);

/**
 * Waits for initial measurements and calibrates the current sensors
 */
void daq_setup(void);

/**
 * Set lv side (battery) voltage limits where an alert should be triggered
 *
 * @param lv_overvoltage Upper voltage limit
 * @param lv_undervoltage Lower voltage limit
 */
void daq_set_lv_limits(float lv_overvoltage, float lv_undervoltage);

/**
 * Set hv side (grid/solar) voltage limit where an alert should be triggered
 *
 * @param hv_overvoltage Upper voltage limit
 */
void daq_set_hv_limit(float hv_overvoltage);

#ifdef __cplusplus
}
#endif

#endif /* DAQ_H_ */
```

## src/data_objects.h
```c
/*
 * Copyright (c) The Libre Solar Project Contributors
 *
 * SPDX-License-Identifier: Apache-2.0
 */

#ifndef DATA_OBJECTS_H_
#define DATA_OBJECTS_H_

/** @file
 *
 * @brief Handling of ThingSet data objects
 */

#include <stdint.h>
#include <string.h>

/*
 * Groups / first layer data object IDs
 */
#define ID_ROOT     0x00
#define ID_DEVICE   0x04
#define ID_BATTERY  0x05
#define ID_CHARGER  0x06
#define ID_SOLAR    0x07
#define ID_LOAD     0x08
#define ID_USB      0x09
#define ID_NANOGRID 0x0A

/**
 * Callback function to be called when conf values were changed
 */
void data_objects_update_conf();

/**
 * Initializes and reads data objects from EEPROM
 */
void data_objects_init();

#endif /* DATA_OBJECTS_H */
```

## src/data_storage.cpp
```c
/*
 * Copyright (c) The Libre Solar Project Contributors
 *
 * SPDX-License-Identifier: Apache-2.0
 */

#include "data_storage.h"

#include <zephyr/kernel.h>

#include "data_objects.h"
#include "helper.h"
#include "mcu.h"
#include "thingset.h"

#include <stdio.h>

#ifdef CONFIG_SOC_FAMILY_STM32

#include <stm32_ll_bus.h>
#include <zephyr/device.h>

LOG_MODULE_REGISTER(nvs, CONFIG_DATA_STORAGE_LOG_LEVEL);

K_MUTEX_DEFINE(data_buf_lock);

// Buffer used by store and restore functions (must be word-aligned for hardware CRC calculation)
static uint8_t buf[512] __aligned(sizeof(uint32_t));

extern ThingSet ts;

uint32_t _calc_crc(const uint8_t *buf, size_t len)
{
    LL_AHB1_GRP1_EnableClock(LL_AHB1_GRP1_PERIPH_CRC);

    // we keep standard polynomial 0x04C11DB7 (same for STM32L0 and STM32F0)
    // and we don't care for endianness here
    CRC->CR |= CRC_CR_RESET;
    for (size_t i = 0; i < len; i += 4) {
        // printf("CRC buf: %.8x, CRC->DR: %.8x\n", *((uint32_t*)&buf[i]), CRC->DR);
        size_t remaining_bytes = len - i;
        if (remaining_bytes >= 4) {
            CRC->DR = *((uint32_t *)&buf[i]);
        }
        else {
            // ignore bytes >= len if len is not a multiple of 4
            CRC->DR = *((uint32_t *)&buf[i]) & (0xFFFFFFFFU >> (32 - remaining_bytes * 8));
        }
    }

    LL_AHB1_GRP1_DisableClock(LL_AHB1_GRP1_PERIPH_CRC);

    return CRC->DR;
}

#endif /* UNIT_TEST */

#ifdef CONFIG_EEPROM

#include <zephyr/drivers/eeprom.h>

/*
 * EEPROM header bytes:
 * - 0-1: Data objects version number
 * - 2-3: Number of data bytes
 * - 4-7: CRC32
 *
 * Data starts from byte 8
 */
#define EEPROM_HEADER_SIZE 8

static const struct device *eeprom_dev = DEVICE_DT_GET(DT_NODELABEL(eeprom));

void data_storage_read()
{
    int err;

    if (!device_is_ready(eeprom_dev)) {
        LOG_ERR("EEPROM device not ready");
        return;
    }

    uint8_t buf_header[EEPROM_HEADER_SIZE] = {};
    err = eeprom_read(eeprom_dev, 0, buf_header, EEPROM_HEADER_SIZE);
    if (err != 0) {
        LOG_ERR("EEPROM read error %d", err);
        return;
    }
    uint16_t version = *((uint16_t *)&buf_header[0]);
    uint16_t len = *((uint16_t *)&buf_header[2]);
    uint32_t crc = *((uint32_t *)&buf_header[4]);

    LOG_DBG("EEPROM header restore: ver %d, len %d, CRC %.8x", version, len, (unsigned int)crc);
    LOG_DBG("Header: %.2x %.2x %.2x %.2x %.2x %.2x %.2x %.2x", buf_header[0], buf_header[1],
            buf_header[2], buf_header[3], buf_header[4], buf_header[5], buf_header[6],
            buf_header[7]);

    if (version == DATA_OBJECTS_VERSION && len <= sizeof(buf)) {
        k_mutex_lock(&data_buf_lock, K_FOREVER);
        err = eeprom_read(eeprom_dev, EEPROM_HEADER_SIZE, buf, len);

        // printf("Data (len=%d): ", len);
        // for (int i = 0; i < len; i++) printf("%.2x ", buf[i]);

        if (_calc_crc(buf, len) == crc) {
            int status = ts.bin_import(buf, sizeof(buf), TS_WRITE_MASK, SUBSET_NVM);
            LOG_INF("EEPROM read and data objects updated, ThingSet result: 0x%x", status);
        }
        else {
            LOG_ERR("EEPROM data CRC invalid, expected 0x%x (data_len = %d)", (unsigned int)crc,
                    len);
        }
        k_mutex_unlock(&data_buf_lock);
    }
    else {
        LOG_INF("EEPROM empty or data layout version changed");
    }
}

void data_storage_write()
{
    int err;

    if (!device_is_ready(eeprom_dev)) {
        LOG_ERR("EEPROM device not ready");
        return;
    }

    k_mutex_lock(&data_buf_lock, K_FOREVER);

    int len = ts.bin_export(buf + EEPROM_HEADER_SIZE, sizeof(buf) - EEPROM_HEADER_SIZE, SUBSET_NVM);
    uint32_t crc = _calc_crc(buf + EEPROM_HEADER_SIZE, len);

    *((uint16_t *)&buf[0]) = (uint16_t)DATA_OBJECTS_VERSION;
    *((uint16_t *)&buf[2]) = (uint16_t)(len);
    *((uint32_t *)&buf[4]) = crc;

    // printf("Data (len=%d): ", len);
    // for (int i = 0; i < len; i++) printf("%.2x ", buf[i + EEPROM_HEADER_SIZE]);

    LOG_DBG("Header: %.2x %.2x %.2x %.2x %.2x %.2x %.2x %.2x", buf[0], buf[1], buf[2], buf[3],
            buf[4], buf[5], buf[6], buf[7]);

    if (len == 0) {
        LOG_ERR("EEPROM data could not be stored. ThingSet error (len = %d)", len);
    }
    else {
        err = eeprom_write(eeprom_dev, 0, buf, len + EEPROM_HEADER_SIZE);
        if (err == 0) {
            LOG_INF("EEPROM data successfully stored");
        }
        else {
            LOG_ERR("EEPROM write error %d", err);
        }
    }
    k_mutex_unlock(&data_buf_lock);
}

#elif defined(CONFIG_NVS)

#include <zephyr/drivers/flash.h>
#include <zephyr/fs/nvs.h>
#include <zephyr/storage/flash_map.h>

/*
 * NVS header bytes:
 * - 0-1: Data objects version number
 *
 * Data starts from byte 2
 */
#define NVS_HEADER_SIZE 2

#define NVS_PARTITION storage_partition

#define THINGSET_DATA_ID 1

static struct nvs_fs fs;
static bool nvs_initialized = false;

static int data_storage_init()
{
    int err;
    struct flash_pages_info page_info;

    fs.flash_device = FIXED_PARTITION_DEVICE(NVS_PARTITION);
    if (!device_is_ready(fs.flash_device)) {
        LOG_ERR("Flash device not ready");
        return -ENODEV;
    }
    fs.offset = FIXED_PARTITION_OFFSET(NVS_PARTITION);
    err = flash_get_page_info_by_offs(fs.flash_device, fs.offset, &page_info);
    if (err) {
        LOG_ERR("Unable to get flash page info");
        return err;
    }
    fs.sector_size = page_info.size;
    fs.sector_count = FIXED_PARTITION_SIZE(NVS_PARTITION) / page_info.size;

    err = nvs_mount(&fs);
    if (err) {
        LOG_ERR("NVS mount failed: %d", err);
        return err;
    }

    nvs_initialized = true;
    return 0;
}

void data_storage_read()
{
    if (!nvs_initialized) {
        int err = data_storage_init();
        if (err) {
            return;
        }
    }

    int num_bytes = nvs_read(&fs, THINGSET_DATA_ID, &buf, sizeof(buf));

    if (num_bytes < 0) {
        LOG_INF("NVS empty (read error %d)", num_bytes);
        return;
    }

    uint16_t version = *((uint16_t *)&buf[0]);

    if (version == DATA_OBJECTS_VERSION) {
        k_mutex_lock(&data_buf_lock, K_FOREVER);

        int status = ts.bin_import(buf + NVS_HEADER_SIZE, num_bytes - NVS_HEADER_SIZE,
                                   TS_WRITE_MASK, SUBSET_NVM);
        LOG_INF("NVS read and data objects updated, ThingSet result: 0x%x", status);

        k_mutex_unlock(&data_buf_lock);
    }
    else {
        LOG_INF("NVS data layout version changed");
    }
}

void data_storage_write()
{
    if (!nvs_initialized) {
        int err = data_storage_init();
        if (err) {
            return;
        }
    }

    k_mutex_lock(&data_buf_lock, K_FOREVER);

    *((uint16_t *)&buf[0]) = (uint16_t)DATA_OBJECTS_VERSION;

    int len = ts.bin_export(buf + NVS_HEADER_SIZE, sizeof(buf) - NVS_HEADER_SIZE, SUBSET_NVM);

    if (len == 0) {
        LOG_ERR("NVS data could not be stored. ThingSet error (len = %d)", len);
    }
    else {
        int ret = nvs_write(&fs, THINGSET_DATA_ID, &buf, len + NVS_HEADER_SIZE);
        if (ret == len + NVS_HEADER_SIZE) {
            LOG_DBG("NVS data successfully stored");
        }
        else if (ret == 0) {
            LOG_DBG("NVS data unchanged");
        }
        else {
            LOG_ERR("NVS write error %d", ret);
        }
    }

    k_mutex_unlock(&data_buf_lock);
}

#else

void data_storage_write()
{}
void data_storage_read()
{}

#endif

void data_storage_update()
{
    if (uptime() % DATA_UPDATE_INTERVAL == 0 && uptime() > 0) {
        data_storage_write();
    }
}
```

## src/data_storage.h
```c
/*
 * Copyright (c) The Libre Solar Project Contributors
 *
 * SPDX-License-Identifier: Apache-2.0
 */

#ifndef DATA_STORAGE_H_
#define DATA_STORAGE_H_

#define DATA_UPDATE_INTERVAL (6 * 60 * 60) // update every 6 hours

/**
 * @file
 *
 * @brief Handling of internal or external EEPROM to store device configuration
 */

/**
 * Store current charge controller data to EEPROM
 */
void data_storage_write();

/**
 * Restore charge controller data from EEPROM and write to variables in RAM
 */
void data_storage_read();

/**
 * Stores data to EEPROM every 6 hours (can be called regularly)
 */
void data_storage_update();

#endif /* DATA_STORAGE_H_ */
```
